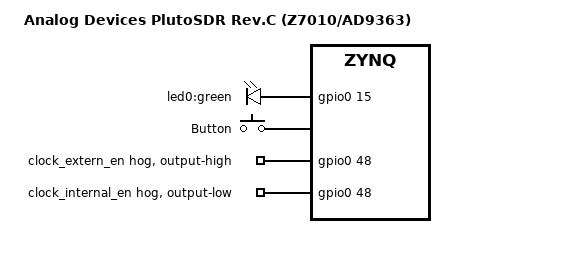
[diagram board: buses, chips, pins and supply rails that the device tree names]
// SPDX-License-Identifier: GPL-2.0
/*
 * hdl_project: <signalsdrpro>
 * board_revision: <C>
 *
 * Copyright (C) 2016-2019 MicroPhase Inc.
 */
/dts-v1/;
#include "zynq-signalsdrpro.dtsi"
#include <dt-bindings/input/input.h>
#include <dt-bindings/gpio/gpio.h>
#include <dt-bindings/interrupt-controller/irq.h>

/* These GPIO hogs are configured by u-boot environment */
&gpio0 {
	clock_extern_en {
		gpio-hog;
		gpios = <48 0>;
		output-high;
	};

	clock_internal_en {
		gpio-hog;
		gpios = <48 0>;
		output-low;
	};
};


&adc0_ad9364 {
	/* This property is controlled by u-boot environment. */
	adi,2rx-2tx-mode-enable;
};

&cf_ad9364_dac_core_0 {
	/* This property is controlled by u-boot environment. */
	compatible = "adi,axi-ad9361-dds-6.00.a";
};

/ {
	model = "Analog Devices PlutoSDR Rev.C (Z7010/AD9363)";

	leds {
		compatible = "gpio-leds";
		led0 {
			label = "led0:green";
			gpios = <&gpio0 15 0>;
			linux,default-trigger = "heartbeat";
		};
	};

	gpio_keys {
		compatible = "gpio-keys";
		#address-cells = <1>;
		#size-cells = <0>;

		button {
			interrupt-parent = <&gpio0>;
			interrupts = <14 IRQ_TYPE_EDGE_FALLING>;
			label = "Button";
			linux,code = <BTN_MISC>;
		};
	};
};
